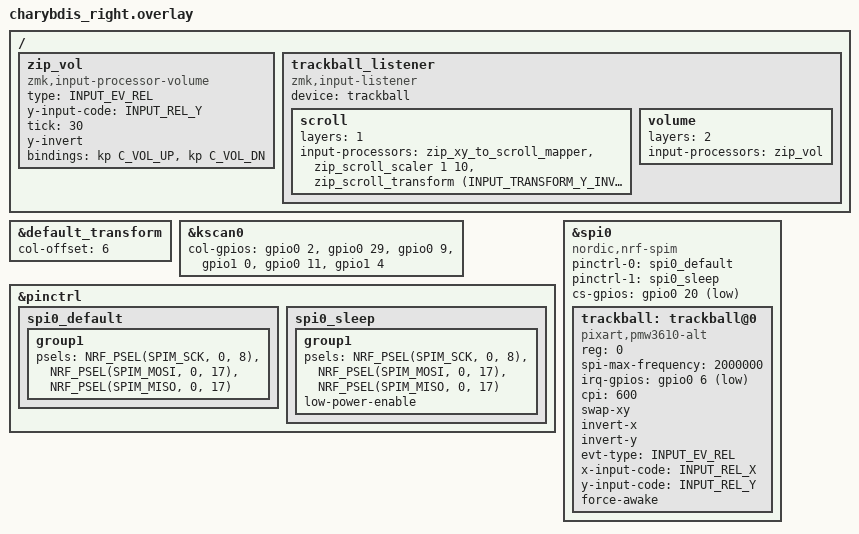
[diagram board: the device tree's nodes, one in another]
/*
 * Copyright (c) 2020 ZMK Contributors
 * SPDX-License-Identifier: MIT
 */

#include "charybdis.dtsi"
#include <zephyr/dt-bindings/input/input-event-codes.h>
#include <input/processors.dtsi>
#include <dt-bindings/zmk/input_transform.h>
#include <dt-bindings/zmk/keys.h>

&default_transform {
    col-offset = <6>;
};

&kscan0 {
    col-gpios
        = <&gpio0 2  (GPIO_ACTIVE_HIGH | GPIO_PULL_DOWN)>
        , <&gpio0 29 (GPIO_ACTIVE_HIGH | GPIO_PULL_DOWN)>
        , <&gpio0 9  (GPIO_ACTIVE_HIGH | GPIO_PULL_DOWN)>
        , <&gpio1 0  (GPIO_ACTIVE_HIGH | GPIO_PULL_DOWN)>
        , <&gpio0 11 (GPIO_ACTIVE_HIGH | GPIO_PULL_DOWN)>
        , <&gpio1 4  (GPIO_ACTIVE_HIGH | GPIO_PULL_DOWN)>
        ;
};

&pinctrl {
    spi0_default: spi0_default {
        group1 {
            psels = <NRF_PSEL(SPIM_SCK, 0, 8)>,
                    <NRF_PSEL(SPIM_MOSI, 0, 17)>,
                    <NRF_PSEL(SPIM_MISO, 0, 17)>;
        };
    };
    spi0_sleep: spi0_sleep {
        group1 {
            psels = <NRF_PSEL(SPIM_SCK, 0, 8)>,
                    <NRF_PSEL(SPIM_MOSI, 0, 17)>,
                    <NRF_PSEL(SPIM_MISO, 0, 17)>;
            low-power-enable;
        };
    };
};

&spi0 {
    status = "okay";
    compatible = "nordic,nrf-spim";
    pinctrl-0 = <&spi0_default>;
    pinctrl-1 = <&spi0_sleep>;
    pinctrl-names = "default", "sleep";
    cs-gpios = <&gpio0 20 GPIO_ACTIVE_LOW>;

    trackball: trackball@0 {
        status = "okay";
        compatible = "pixart,pmw3610-alt";
        reg = <0>;
        spi-max-frequency = <2000000>;
        irq-gpios = <&gpio0 6 (GPIO_ACTIVE_LOW | GPIO_PULL_UP)>;

        cpi = <600>;

        swap-xy;
        invert-x;
        invert-y;    /* invert standard cursor Y axis */

        evt-type = <INPUT_EV_REL>;
        x-input-code = <INPUT_REL_X>;
        y-input-code = <INPUT_REL_Y>;

        force-awake;
    };
};

/ {
    /*
     * Volume processor.
     *
     * On REL_Y: accumulates delta, fires C_VOL_UP or C_VOL_DN, then remaps
     * event->code to INPUT_REL_MISC so handle_rel_code() in the listener
     * ignores it — no cursor movement, no remainder bleed between layers.
     *
     * On REL_X: also remapped to INPUT_REL_MISC, suppressing horizontal
     * cursor movement on the volume layer.
     *
     * No separate zeroing processor needed in the overlay — suppression is
     * handled inside the module, the same way zip_xy_to_scroll_mapper works.
     *
     * y-invert: inverts volume Y independently of the device-level invert-y.
     */
    zip_vol: zip_vol {
        compatible = "zmk,input-processor-volume";
        #input-processor-cells = <0>;
        type = <INPUT_EV_REL>;
        y-input-code = <INPUT_REL_Y>;
        tick = <30>;
        y-invert;
        bindings = <&kp C_VOL_UP>, <&kp C_VOL_DN>;
    };

    trackball_listener: trackball_listener {
        compatible = "zmk,input-listener";
        device = <&trackball>;

        /* Layer 1 — scroll */
        scroll {
            layers = <1>;
            input-processors = <&zip_xy_to_scroll_mapper>,
                               <&zip_scroll_scaler 1 10>,
                               <&zip_scroll_transform (INPUT_TRANSFORM_Y_INVERT)>;
        };

        /* Layer 2 — volume only.
         * zip_vol remaps both axes to REL_MISC internally after consuming
         * REL_Y for volume — no cursor movement, no extra processors needed. */
        volume {
            layers = <2>;
            input-processors = <&zip_vol>;
        };
    };
};
